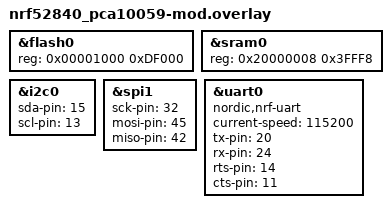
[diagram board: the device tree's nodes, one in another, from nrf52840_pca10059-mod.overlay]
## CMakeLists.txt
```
cmake_minimum_required(VERSION 3.8.2)
set(QEMU_EXTRA_FLAGS -s)

#######################################################
### OPTIONS ###    REMEMBER TO RUN cmake.sh WHEN    ###
#                   YOU MAKE CHANGES IN OPTIONS!    ###
#######################################################

# typical options for USB dongle pca10059 (comment next 3 lines if NOT USB dongle)
OPTION(DEBUG "Set this ON for debug mode (on SDK shows dbg_log messages)" OFF)
OPTION(USB_DONGLE "Set this ON for USB dongle version" ON)
OPTION(BT_MAC "Set this to force hardcoded BT MAC address" OFF)

# typical options for SDK board pca10056 (comment next 3 lines if NOT USDK board)
#OPTION(DEBUG "Set this ON for debug mode (on SDK shows dbg_log messages)" ON)
#OPTION(USB_DONGLE "Set this ON for USB dongle version" OFF)
#OPTION(BT_MAC "Set this to force hardcoded BT MAC address" ON)

IF(USB_DONGLE)
  SET(BOARD nrf52840_pca10059)
  ADD_DEFINITIONS(-DUSB_DONGLE)
ELSE()
  SET(BOARD nrf52840_pca10056)
  IF(DEBUG)
    ADD_DEFINITIONS(-DDEBUG)
    SET(CMAKE_BUILD_TYPE Debug)
  ENDIF()
ENDIF()

IF(BT_MAC)
  ADD_DEFINITIONS(-DBT_MAC)
ENDIF()

ADD_DEFINITIONS(-DIN3_MATH_LITE)

#######################################################

include($ENV{ZEPHYR_BASE}/cmake/app/boilerplate.cmake NO_POLICY_SCOPE)
project(NONE)

target_sources(app PRIVATE
	src/main.c
	src/fsm.c
	src/rent.c
)

# include core in the headers
include_directories ("${PROJECT_SOURCE_DIR}/../core")
#include_directories ("${PROJECT_SOURCE_DIR}/../eth_full")
include_directories ("${PROJECT_SOURCE_DIR}/../eth_nano")
#include_directories ("${PROJECT_SOURCE_DIR}/../eth_basic")
include(../core/include.cmake)

# choose which module to include
#include(../eth_basic/include.cmake)
include(../eth_nano/include.cmake)
include(../core/compiler.cmake)
set_property(GLOBAL PROPERTY C_STANDARD 99)

# add dependency
# add_subdirectory( ../core "${PROJECT_BINARY_DIR}/core")
#target_link_libraries(app core)
```

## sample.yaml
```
sample:
  description: in3 receiver
  name: in3-receiver
  platforms: all
common:
    tags: samples
    harness: console
    harness_config:
      type: one_line
      regex:
        - "Hello World! (.*)"
tests:
  sample.helloworld.singlethread:
    extra_args: CONF_FILE=prj_single.conf
    filter: not CONFIG_BT and not CONFIG_GPIO_SCH and ASSERT == 0
  sample.helloworld.multithread:
    tags: samples
```

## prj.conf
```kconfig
CONFIG_PRINTK=y
#CONFIG_HEAP_MEM_POOL_SIZE=131072
CONFIG_HEAP_MEM_POOL_SIZE=98304
#CONFIG_MAIN_STACK_SIZE=8192
CONFIG_MAIN_STACK_SIZE=12288
CONFIG_SYSTEM_WORKQUEUE_STACK_SIZE=4096

CONFIG_RTT_CONSOLE=n

CONFIG_GPIO=y
CONFIG_BT=y
CONFIG_BT_DEBUG_LOG=n
CONFIG_BT_PERIPHERAL=y
CONFIG_BT_PRIVACY=n
CONFIG_BT_ATT_PREPARE_COUNT=2
CONFIG_BT_GATT_CLIENT=y
CONFIG_BT_L2CAP_DYNAMIC_CHANNEL=n
CONFIG_BT_TINYCRYPT_ECC=n
CONFIG_BT_DEVICE_NAME="in3-peripheral"
CONFIG_BT_DEVICE_NAME_DYNAMIC=y
CONFIG_BT_DEVICE_NAME_MAX=20
CONFIG_BT_ID_MAX=4
CONFIG_BT_RX_BUF_COUNT=10
CONFIG_BT_RX_BUF_LEN=258
CONFIG_BT_L2CAP_TX_MTU=247
CONFIG_BT_L2CAP_TX_FRAG_COUNT=6
CONFIG_BT_L2CAP_TX_BUF_COUNT=10
CONFIG_BT_CONN_TX_MAX=10
CONFIG_BT_ATT_PREPARE_COUNT=10
CONFIG_BT_ID_MAX=4
CONFIG_BT_CTLR_RX_BUFFERS=10
CONFIG_BT_CTLR_TX_BUFFERS=10
CONFIG_BT_CTLR_TX_BUFFER_SIZE=251
CONFIG_BT_CTLR_DATA_LENGTH_MAX=251

CONFIG_BT_SETTINGS=y
CONFIG_FLASH=y
CONFIG_FLASH_PAGE_LAYOUT=y
CONFIG_FLASH_MAP=y
CONFIG_FCB=y
CONFIG_SETTINGS=y
CONFIG_SETTINGS_FCB=y

# config PWM
#-----------
CONFIG_PWM=y
CONFIG_PWM_NRF5_SW=y
CONFIG_PWM_NRF5_SW_0_CLOCK_PRESCALER=4
```

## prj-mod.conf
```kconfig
# config console and stdout
#--------------------------
CONFIG_CONSOLE_SUBSYS=y
CONFIG_CONSOLE_GETCHAR=y
CONFIG_STDOUT_CONSOLE=y
CONFIG_UART_CONSOLE=y
CONFIG_RTT_CONSOLE=n
CONFIG_PRINTK=y

# config UART
#------------
CONFIG_UART_NRFX=y
CONFIG_UART_0_NRF_UART=y
CONFIG_UART_0_NRF_FLOW_CONTROL=n

# config I/O
#-----------
CONFIG_GPIO=y
# NOTE: P0.09 and P0.10 usually set for NFC; to free them use next line
CONFIG_NFCT_PINS_AS_GPIOS=y

# config SPI
#-----------
CONFIG_SPI=y
CONFIG_SPI_NRFX=y
CONFIG_SPI_1=y
CONFIG_SPI_1_NRF_SPI=y

# config I2C
#-----------
CONFIG_I2C=y
CONFIG_I2C_NRFX=y
CONFIG_I2C_0=y
CONFIG_I2C_0_NRF_TWI=y

# config PWM
#-----------
CONFIG_PWM=y
CONFIG_PWM_NRF5_SW=y
CONFIG_PWM_NRF5_SW_0_CLOCK_PRESCALER=4

# config RTOS
#------------
#CONFIG_HEAP_MEM_POOL_SIZE=131072
CONFIG_HEAP_MEM_POOL_SIZE=98304
#CONFIG_MAIN_STACK_SIZE=8192
CONFIG_MAIN_STACK_SIZE=12288
CONFIG_SYSTEM_WORKQUEUE_STACK_SIZE=4096

# config flash
#-------------
#CONFIG_FLASH=y
#CONFIG_FLASH_PAGE_LAYOUT=y
#CONFIG_FLASH_MAP=y
#CONFIG_FCB=y
#CONFIG_SETTINGS=y
#CONFIG_SETTINGS_FCB=y

# config Bluetooth
#-----------------
CONFIG_BT_SETTINGS=n
# n means that state and configuration are NOT stored permanently
CONFIG_BT_DEBUG_LOG=n
# we don't need debug info for bluetooth (at least, I hope so)
CONFIG_BT_PRIVACY=n
# local privacy not enabled
CONFIG_BT_PERIPHERAL=y
# set LE Peripheral role support
CONFIG_BT_DEVICE_APPEARANCE=384
# 384 = BLE_APPEARANCE_GENERIC_REMOTE_CONTROL 
CONFIG_BT_DEVICE_NAME_DYNAMIC=y
# can change the BLE name dinamically (see bluetooth init in main.c)
CONFIG_BT_DEVICE_NAME_MAX=24
# max length allowed for the name 

#CONFIG_BT_L2CAP_TX_MTU=247
# change max allowable MTU
# note: in this case MTU is not changed from the default (23)
#       for compatibility with Android 5; any request will return 23

CONFIG_BT=y
#CONFIG_BT_SETTINGS=y
CONFIG_BT_PERIPHERAL=y
CONFIG_BT_ATT_PREPARE_COUNT=2
CONFIG_BT_GATT_CLIENT=y
CONFIG_BT_L2CAP_DYNAMIC_CHANNEL=n
CONFIG_BT_TINYCRYPT_ECC=n
CONFIG_BT_DEVICE_NAME="in3-peripheral"
CONFIG_BT_ID_MAX=4
CONFIG_BT_RX_BUF_COUNT=10
CONFIG_BT_RX_BUF_LEN=258
CONFIG_BT_L2CAP_TX_MTU=247
CONFIG_BT_L2CAP_TX_FRAG_COUNT=6
CONFIG_BT_L2CAP_TX_BUF_COUNT=10
CONFIG_BT_CONN_TX_MAX=10
CONFIG_BT_ATT_PREPARE_COUNT=10
CONFIG_BT_ID_MAX=4
CONFIG_BT_CTLR_RX_BUFFERS=10
CONFIG_BT_CTLR_TX_BUFFERS=10
CONFIG_BT_CTLR_TX_BUFFER_SIZE=251
CONFIG_BT_CTLR_DATA_LENGTH_MAX=251
```

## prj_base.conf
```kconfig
# nothing here
CONFIG_SCHED_MULTIQ=y
CONFIG_PRINTK=y
CONFIG_HEAP_MEM_POOL_SIZE=65536
#CONFIG_MPU_ALLOW_FLASH_WRITE=y

CONFIG_MAIN_STACK_SIZE=512
CONFIG_SYSTEM_WORKQUEUE_STACK_SIZE=2048

CONFIG_BT_SETTINGS=y
CONFIG_FLASH=y
CONFIG_FLASH_PAGE_LAYOUT=y
CONFIG_FLASH_MAP=y
CONFIG_FCB=y
CONFIG_SETTINGS=y
CONFIG_SETTINGS_FCB=y
CONFIG_BT_MESH_RPL_STORE_TIMEOUT=600

CONFIG_BOOT_BANNER=y
CONFIG_BUILD_TIMESTAMP=y

CONFIG_BT_OBSERVER=y
CONFIG_BT_BROADCASTER=y
CONFIG_BT_CTLR_DUP_FILTER_LEN=0
CONFIG_BT_CTLR_LE_ENC=n
CONFIG_BT_CTLR_LE_PING=n
CONFIG_BT_CTLR_DATA_LENGTH=n
CONFIG_BT_CTLR_PHY=n
CONFIG_BT_CTLR_CHAN_SEL_2=n
CONFIG_BT_CTLR_MIN_USED_CHAN=n
CONFIG_BT_CTLR_ADV_EXT=n
CONFIG_BT_CTLR_PRIVACY=n

CONFIG_BT_PERIPHERAL=y

CONFIG_BT=y
CONFIG_BT_TINYCRYPT_ECC=y
CONFIG_BT_RX_BUF_COUNT=30
CONFIG_BT_L2CAP_RX_MTU=69
CONFIG_BT_L2CAP_TX_MTU=69
CONFIG_BT_L2CAP_TX_BUF_COUNT=8

CONFIG_BT_MESH=y
CONFIG_BT_MESH_RELAY=y
CONFIG_BT_MESH_LOW_POWER=n
CONFIG_BT_MESH_FRIEND=n
CONFIG_BT_MESH_FRIEND_QUEUE_SIZE=16
CONFIG_BT_MESH_ADV_BUF_COUNT=20
#CONFIG_BT_MESH_TX_SEG_MAX=6

CONFIG_BT_MESH_PB_GATT=y
CONFIG_BT_MESH_PB_ADV=y
CONFIG_BT_MESH_GATT_PROXY=y
CONFIG_BT_MESH_CFG_CLI=y

#CONFIG_BT_MESH_LPN_SCAN_LATENCY=30
#CONFIG_BT_MESH_LPN_RECV_DELAY=40
#CONFIG_BT_MESH_LPN_POLL_TIMEOUT=300

CONFIG_BT_MESH_SUBNET_COUNT=2
CONFIG_BT_MESH_APP_KEY_COUNT=2
CONFIG_BT_MESH_MODEL_KEY_COUNT=2
CONFIG_BT_MESH_MODEL_GROUP_COUNT=2
CONFIG_BT_MESH_LABEL_COUNT=3

#CONFIG_BT_MESH_IV_UPDATE_TEST=y

CONFIG_UART_CONSOLE=y

# this outputs btmon formatted data to the serial port
#CONFIG_BT_DEBUG_MONITOR=y

#CONFIG_SYS_LOG=y
CONFIG_SYS_LOG_DEFAULT_LEVEL=4
CONFIG_SYS_LOG_EXT_HOOK=y
CONFIG_BT_DEBUG_LOG=y

CONFIG_BT_MESH_DEBUG=y
#CONFIG_BT_MESH_DEBUG_PROV=y
#CONFIG_BT_MESH_DEBUG_PROXY=y
#CONFIG_BT_MESH_DEBUG_BEACON=y
#CONFIG_BT_MESH_DEBUG_NET=y
#CONFIG_BT_MESH_DEBUG_TRANS=y
#CONFIG_BT_MESH_DEBUG_LOW_POWER=y
#CONFIG_BT_MESH_DEBUG_FRIEND=y
#CONFIG_BT_MESH_DEBUG_MODEL=y
#CONFIG_BT_MESH_DEBUG_ACCESS=y
#CONFIG_BT_MESH_DEBUG_CRYPTO=y
#CONFIG_BT_MESH_DEBUG_ADV=y
#CONFIG_BT_MESH_SELF_TEST=y

#CONFIG_BT_HCI_VS_EXT=n

#CONFIG_STACK_USAGE=y

CONFIG_BT_RX_STACK_SIZE=4096

#CONFIG_BT_DEBUG_HCI_DRIVER=y
#CONFIG_BT_DEBUG_HCI_CORE=y
#CONFIG_BT_DEBUG_GATT=y
#CONFIG_BT_DEBUG_CONN=y

CONFIG_BT_MAX_CONN=1
CONFIG_BT_CTLR_RX_BUFFERS=6
CONFIG_BT_CTLR_TX_BUFFERS=4
CONFIG_BT_HCI_CMD_COUNT=4

CONFIG_BT_ATT_PREPARE_COUNT=2

#CONFIG_NET_BUF_SIMPLE_LOG=y
#CONFIG_SYS_LOG_NET_BUF_LEVEL=4
#CONFIG_NET_BUF_LOG=y
#CONFIG_BT_CTLR_DEBUG_PINS=y
```

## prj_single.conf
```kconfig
CONFIG_MULTITHREADING=n
```

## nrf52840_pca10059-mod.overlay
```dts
&flash0 {
	reg = <0x00001000 0xDF000>;
};

&sram0 {
	reg = <0x20000008 0x3FFF8>;
};

&i2c0 {
	status = "ok";
	sda-pin = <15>;
	scl-pin = <13>;
};

&spi1 {
	status = "ok";
	sck-pin = <32>;
	mosi-pin = <45>;
	miso-pin = <42>;
};

&uart0 {
	compatible = "nordic,nrf-uart";
	current-speed = <115200>;
	status = "ok";
	tx-pin = <20>;
	rx-pin = <24>;
	rts-pin = <14>;
	cts-pin = <11>;
};
```

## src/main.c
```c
#include <stdio.h>
#include <string.h>
#include <zephyr.h>
#include <misc/util.h>
#include <kernel.h>
#include <misc/printk.h>
#include <string.h>
#include <gpio.h>
#include <device.h>
#include <pwm.h>

#include <settings/settings.h>

#include <bluetooth/hci.h>
#include <bluetooth/gatt.h>
#include <bluetooth/bluetooth.h>
#include <bluetooth/conn.h>
#include <bluetooth/l2cap.h>
#include <bluetooth/rfcomm.h>
#include <bluetooth/sdp.h>

#include "fsm.h"
#include "util/utils.h"
#include "util/bytes.h"

#include "util/debug.h"

// prototypes:
void bt_dev_show_info(void);
int start_message(int size);
void process_msg(void);

// variables:
static struct bt_conn *default_conn = NULL;
static struct bt_gatt_ccc_cfg req_ccc_cfg[BT_GATT_CCC_MAX] = {};

static u32_t cnt;
struct device *ledpower; // green led (power)
struct device *ledstrip; // led strip (used as lamp)
struct device *lockpin; // lock out
struct device *gpio; // using blue led on usb board for testing
struct device *pwm_dev; // door servo driver
//struct device *demoRled; // USB demo Rled
//struct device *demoGled; // USB demo Gled
//struct device *demoBled; // USB demo Bled
 
/*
static u8_t gbuff1[32768]; // test buffer -DEBUG ONLY-
static u8_t gbuff2[32768]; // test buffer -DEBUG ONLY-
static u8_t gbuff3[32768]; // test buffer -DEBUG ONLY-
static u8_t gbuff4[8192]; // test buffer -DEBUG ONLY-
*/

static u8_t recv_buf_static[512];
static u8_t req_buf[512];

static u8_t *recv_buf;
static u32_t b_off;
static u32_t total_len;

static u32_t start, end;
static struct in3_client *client;

/////////////////////////////
// callbacks for BT services:
//
static ssize_t read_req(struct bt_conn *conn, const struct bt_gatt_attr *attr, // callback from: BT_GATT_CHARACTERISTIC (req_char_uuid)
			void *buf, u16_t len, u16_t offset)
{
	const char *value = attr->user_data;
	u16_t value_len;

	dbg_log("<--- read req (len=%u ofs=%u)\n", len, offset);

	value_len = min(strlen(value), sizeof(req_buf)); // limit the length to req_buf size

	return bt_gatt_attr_read(conn, attr, buf, len, offset, value, value_len);
}

static ssize_t rx_data(struct bt_conn *conn, const struct bt_gatt_attr *attr,
			 const void *buf, u16_t len, u16_t offset,
			 u8_t flags)
{
	dbg_log("<--- len:%u\n", len);
	// if processing a message don't take new ones
	if (client->msg->ready)
		{
		dbg_log("<--- write req rejected (another message being processed)!!!\n");
		return BT_GATT_ERR(BT_ATT_ERR_WRITE_REQ_REJECTED);
		}
/*
	if (total_len == 0) {
		int mtu = bt_gatt_get_mtu(conn) - 3;
		dbg_log(" GATT MTU: %d, DATA_SIZE: %d len=%d\n", mtu+3, mtu, len);
	}
*/
	if (len == 0x8) {
		char magic[17];
		char *header = (char *) buf;
		if (total_len > 0) {
			dbg_log("<--- Channel already open, dismissing new request\n");
			return BT_GATT_ERR(BT_ATT_ERR_WRITE_REQ_REJECTED);
		}
		sprintf(magic, "%02x%02x%02x%02x%02x%02x%02x%02x", header[0], header[1],
			header[2], header[3], header[4], header[5], header[6], header[7]);
		if (header[0] == 0x69 &&
		    header[1] == 0x6e &&
		    header[2] == 0x33 &&
		    header[3] == 0x63) {
			dbg_log("<--- Magic: 0x%s\n", magic);
			if (start_message(*((int *) buf+1)))
				{
				dbg_log("<--- offset error\n");
				return BT_GATT_ERR(BT_ATT_ERR_INVALID_OFFSET);
				}
			bluetooth_clear_req();
			return len;
		}
	}

	if(recv_buf == 0) // if no space allocated
		recv_buf = k_calloc(1, total_len);
	////////////////////////////////////////////////////

	memcpy(recv_buf + b_off, buf, len);
	b_off += len;

	if (b_off >= total_len) {
		end = k_uptime_get_32();
		process_msg();
	}

	return len;
}

static void req_ccc_cfg_changed(const struct bt_gatt_attr *attr, u16_t value) // Callback from: BT_GATT_CCC (req_ccc_cfg, req_ccc_cfg_changed)
{
	dbg_log("<--- value = %u\n", value);
}

// define an UUID for msg_svc (BT_GATT_PRIMARY_SERVICE)
static struct bt_uuid_128 msg_svc_uuid = BT_UUID_INIT_128(
	0x01, 0xde, 0xbc, 0x9a, 0x78, 0x56, 0x34, 0x12,
	0x78, 0x56, 0x34, 0x12, 0x78, 0x56, 0x34, 0x12);

// define an UUID for msg_char (BT_GATT_CHARACTERISTIC #1)
static const struct bt_uuid_128 msg_char_uuid = BT_UUID_INIT_128(
	0x02, 0xde, 0xbc, 0x9a, 0x78, 0x56, 0x34, 0x12,
	0x78, 0x56, 0x34, 0x12, 0x78, 0x56, 0x34, 0x12);

// define an UUID for req_char (BT_GATT_CHARACTERISTIC #2)
static const struct bt_uuid_128 req_char_uuid = BT_UUID_INIT_128(
	0x02, 0xde, 0xbc, 0x9a, 0x78, 0x56, 0x34, 0x12,
	0x78, 0x56, 0x34, 0x12, 0x78, 0x56, 0x34, 0x13);

// define an UUID for notify (BT_GATT_CHARACTERISTIC #3)
static const struct bt_uuid_128 notify_uuid = BT_UUID_INIT_128(
	0x02, 0xde, 0xbc, 0x9a, 0x78, 0x56, 0x34, 0x12,
	0x78, 0x56, 0x34, 0x12, 0x78, 0x56, 0x34, 0x14);

static struct bt_gatt_attr msg_attrs[] = {
		BT_GATT_PRIMARY_SERVICE(&msg_svc_uuid), // [0] primary service

////////////////////////////////////////////////////////////////////////
		BT_GATT_CHARACTERISTIC(&msg_char_uuid.uuid, // [1] characteristic attribute uuid
			BT_GATT_CHRC_WRITE, // char att properties
			BT_GATT_PERM_WRITE | BT_GATT_PERM_PREPARE_WRITE, // char att permissions
			NULL, rx_data, recv_buf_static), // char att read callback, write callback, value

		BT_GATT_CHARACTERISTIC(&req_char_uuid.uuid, // [2] characteristic attribute uuid
			BT_GATT_CHRC_READ, // char att properties
			BT_GATT_PERM_READ, // char att permissions
			read_req, NULL, req_buf), // char att read callback, write callback, value

		BT_GATT_CHARACTERISTIC(&notify_uuid.uuid, // [3] characteristic attribute uuid
			BT_GATT_CHRC_NOTIFY, // char att properties
			BT_GATT_PERM_NONE, // char att permissions
			NULL, NULL, NULL), // char att read callback, write callback, value
////////////////////////////////////////////////////////////////////////

		BT_GATT_CCC(req_ccc_cfg, req_ccc_cfg_changed), // [4] initial config, callback to configuration change
};

////////
// Code:
//
int start_message(int size)
{
	int old_len = total_len;
	total_len = size;
	dbg_log("RX Message (length: %lu bytes)\n", total_len);

	if (recv_buf && (old_len > total_len)) {
		memset(recv_buf, 0, total_len);
		goto out;
	}

	if (recv_buf)
		k_free(recv_buf);

	recv_buf = k_calloc(1, total_len * sizeof(char));

out:
	if (!recv_buf) {
		dbg_log("Error allocating RX buf (size=%lu)\n", total_len);
		return -1;
	}

	start = k_uptime_get_32();

	k_mutex_lock(&client->mutex, 5000);

	return 0;
}

void process_msg(void)
{
	client->msg->data = recv_buf;
	client->msg->size = total_len;

	client->msg->ready = 1;

	b_off = 0;
	total_len = 0;

	k_mutex_unlock(&client->mutex);
	in3_signal_event();
}

void clear_message(struct in3_client *c)
{
	// EFmod: in case of raw message received, msg->ready flag will NOT be reset
	//  and this may hang the program; so, do this anyway:
	c->msg->ready = 0; // EFmod - may be also this is unassigned

	if (!recv_buf)
		return;

	k_free(recv_buf);

	c->msg->size = 0;
	c->msg->ready = 0;

	b_off = 0;
	total_len = 0;

	recv_buf = 0;
	c->msg->data = 0;
}

static struct bt_gatt_service msg_svc = BT_GATT_SERVICE(msg_attrs);

static const struct bt_data ad_discov[] = {
	BT_DATA_BYTES(BT_DATA_FLAGS, (BT_LE_AD_GENERAL | BT_LE_AD_NO_BREDR)),
};

static void connected(struct bt_conn *conn, u8_t err)
{
	dbg_log("<---\n"); // function is shown on the left
	default_conn = conn;
}

static void disconnected(struct bt_conn *conn, u8_t reason)
{
	dbg_log("<---\n"); // function is shown on the left
}

static bool le_param_req(struct bt_conn *conn, struct bt_le_conn_param *param)
{
int mtu = bt_gatt_get_mtu(conn);

	dbg_log("<--- req MTU=%d\n", mtu);
	return true;
}

static void le_param_updated(struct bt_conn *conn, u16_t interval, u16_t latency, u16_t timeout)
{
int mtu = bt_gatt_get_mtu(conn);

	dbg_log("<--- upd MTU=%d\n", mtu);
	return;
}

static struct bt_conn_cb conn_cbs = {
	.connected = connected,
	.disconnected = disconnected,
	.le_param_req = le_param_req,
	.le_param_updated = le_param_updated,
};

static void bt_ready(int err)
{
	default_conn = NULL;
	bt_conn_cb_register(&conn_cbs);
}

void bluetooth_write_req(char *msg)
{
	k_mutex_lock(&client->mutex, 5000);

	if (strlen(msg) > sizeof(recv_buf_static)) // EFmod: may be req_buf ?
		return;

	strcpy(req_buf, msg);
	dbg_log("<--- buffer prepared for req_char:\n%s\n", req_buf);

	k_mutex_unlock(&client->mutex);

	dbg_log("send notification for REQ\n");

	char *send = "REQ_READY";
//  EFmod: the "normal" [3] does not work. Index [5] is out of bounds, but it works...
	bt_gatt_notify(NULL, &msg_attrs[5], send, strlen(send));
}

void bluetooth_clear_req(void)
{
	memset(req_buf, 0, sizeof(recv_buf_static)); // EFmod: may be sizeof(req_buf) ?
}

#ifdef BT_MAC // START block: next 3 functions needed only if hardcoded BT MAC is enabled
///////////////////////////////////////////////////////////////////////////////
static int char2hex(const char *c, u8_t *x)
{
	if (*c >= '0' && *c <= '9') {
		*x = *c - '0';
	} else if (*c >= 'a' && *c <= 'f') {
		*x = *c - 'a' + 10;
	} else if (*c >= 'A' && *c <= 'F') {
		*x = *c - 'A' + 10;
	} else {
		return -EINVAL;
	}

	return 0;
}

static int str2bt_addr(const char *str, bt_addr_t *addr)
{
	int i, j;
	u8_t tmp;

	if (strlen(str) != 17) {
		return -EINVAL;
	}

	for (i = 5, j = 1; *str != '\0'; str++, j++) {
		if (!(j % 3) && (*str != ':')) {
			return -EINVAL;
		} else if (*str == ':') {
			i--;
			continue;
		}

		addr->val[i] = addr->val[i] << 4;

		if (char2hex(str, &tmp) < 0) {
			return -EINVAL;
		}

		addr->val[i] |= tmp;
	}

	return 0;
}

static int str2bt_addr_le(const char *str, const char *type, bt_addr_le_t *addr)
{
	int err;

	err = str2bt_addr(str, &addr->a);
	if (err < 0) {
		return err;
	}

	if (!strcmp(type, "public") || !strcmp(type, "(public)")) {
		addr->type = BT_ADDR_LE_PUBLIC;
	} else if (!strcmp(type, "random") || !strcmp(type, "(random)")) {
		addr->type = BT_ADDR_LE_RANDOM;
	} else {
		return -EINVAL;
	}

	return 0;
}
#endif
///////////////////////////////////////////////////////////////////// END block

static void byte_to_hex(uint8_t b, char *s)
{
	s[0] = (b / 16) + '0'; // get high nibble, add ascii '0'
	if(s[0] > '9') s[0] += 7; // convert 10..15 to 'A'..'F' (+= 39 if 'a'..'f')
	s[1] = (b & 15) + '0'; // get low nibble, add ascii '0'
	if(s[1] > '9') s[1] += 7; // convert 10..15 to 'A'..'F' (+= 39 if 'a'..'f')
	s[2] = '\0'; // null terminate
}

int bluetooth_setup(struct in3_client *c)
{
	int err, lnam, fmac;
	size_t ad_len, scan_rsp_len = 0;
	struct bt_le_adv_param param;
	const struct bt_data *ad = 0, *scan_rsp = 0;
	char deviceName[20] = "in3-"; // look in prj.con (max length fixed to 20 chars)

#ifdef BT_MAC // if enabled, hardcode the BT MAC address
	bt_addr_le_t addr;
//	char *c_addr = "d3:6c:29:4b:6b:45";
	char *c_addr = "c0:00:00:00:00:00"; // EFmod: most significative 2 bits must be 1
	char *c_addr_type = "(random)";
	err = str2bt_addr_le(c_addr, c_addr_type, &addr);
	bt_set_id_addr((const bt_addr_le_t *) &addr);
#endif

	err = bt_enable(bt_ready);
	if (err) {
		dbg_log("Unable to setup bluetooth");
		return -1;
	}

	k_sleep(1000);
	bt_dev_show_info();

	param.id = 0;
	param.interval_min = BT_GAP_ADV_FAST_INT_MIN_2;
	param.interval_max = BT_GAP_ADV_FAST_INT_MAX_2;
	param.options = (BT_LE_ADV_OPT_CONNECTABLE |
				 BT_LE_ADV_OPT_USE_NAME);
	ad = ad_discov;
	ad_len = ARRAY_SIZE(ad_discov);

	if (IS_ENABLED(CONFIG_SETTINGS)) {
		settings_load();
	}

	fmac = NRF_FICR->DEVICEADDR[0]; // get low 4 octets of BT MAC
	lnam = strlen(deviceName); // original name length (before adding the MAC)
    byte_to_hex((fmac & 0xFF000000) >> 24, deviceName +lnam); // add MAC[3]
    byte_to_hex((fmac & 0xFF0000) >> 16, deviceName +lnam +2); // add MAC[2]
    byte_to_hex((fmac & 0xFF00) >> 8, deviceName +lnam +4); // add MAC[1]
    byte_to_hex(fmac & 0xFF, deviceName +lnam +6); // add MAC[0] (byte_to_hex adds \0)
//	bt_set_name(deviceName); // BT name built with "in3-" and NORDIC (almost) unique BT MAC (es: in3-84C8C54B)
	bt_set_name("in3-emiliotest"); // EFmod: use ONLY this for testing with Arda's App

	err = bt_le_adv_start(&param, ad, ad_len, scan_rsp, scan_rsp_len);
	if (err < 0) {
		dbg_log("Failed to start advertising (err %d)\n", err);
		return -1;
	} else {
		dbg_log("Advertising started\n");
	}

	// set client data
	client = c;
	client->msg->data = recv_buf;

	recv_buf = 0;
	b_off = 0;
	total_len = 0;

	dbg_log("Registering GATT service\n");
	err = bt_gatt_service_register(&msg_svc);

	if (err < 0) {
		dbg_log("Failed to register servic\n");
		return -1;
	} else {
		dbg_log("Service registered\n");
	}

	return 0;
}

///////// new GPIO functions
void ledpower_set(int state)
{
	if(state) // if ON
		gpio_pin_write(ledpower, LEDPOWER, 0); // led with negative logic
	else // if OFF
		gpio_pin_write(ledpower, LEDPOWER, 1); // led with negative logic
}

void ledstrip_set(int state)
{
	if(state) // if ON
		gpio_pin_write(ledstrip, LEDSTRIP, 1); // led with positive logic
	else { // if OFF
		gpio_pin_write(ledstrip, LEDSTRIP, 0); // led with positive logic
//		gpio_pin_write(demoGled, LEDG, 1); // negative logic, green led OFF
//		gpio_pin_write(demoRled, LEDR, 1); // negative logic, red led OFF
	}
}

void lock_set(int state)
{
	if(state) // if ON
		gpio_pin_write(lockpin, LOCKPIN, 1); // coil with positive logic
	else // if OFF
		gpio_pin_write(lockpin, LOCKPIN, 0); // coil with positive logic
}

void door_control(int state) // control the motorized door 
{
	if(state == 'o') { // open door
		pwm_pin_set_usec(pwm_dev, 2, 40000, 2000); // P0.2 - 40ms period - 2 mS pulse; piston All-out
//		gpio_pin_write(demoGled, LEDG, 0); // negative logic, green led ON
		return;
	}
	if(state == 'c') { // close door
//		gpio_pin_write(demoRled, LEDR, 0); // negative logic, red led ON
		pwm_pin_set_usec(pwm_dev, 2, 40000, 1000); // P0.2 - 40mS period - 1mS pulse; piston All-in
		return;
	}
}

int gpio_setup(void)
{
	// PWM init ////////////////////////////////////////////////////////
	pwm_dev = device_get_binding("PWM_0");
	if (!pwm_dev) {
		printk("Cannot find PWM device!\n");
	}
	pwm_pin_set_usec(pwm_dev, 2, 40000, 1000); // P0.2 - 40mS period - 1mS pulse; piston All-in (door closed)

	ledpower = device_get_binding(LEDPOWER_PORT); // CONFIG_GPIO_P0_DEV_NAME
	gpio_pin_configure(ledpower, LEDPOWER, GPIO_DIR_OUT); // set as output (see fsm.h)
	ledpower_set(IO_ON);

	ledstrip = device_get_binding(LEDSTRIP_PORT);
	gpio_pin_configure(ledstrip, LEDSTRIP, GPIO_DIR_OUT); // set as output (see fsm.h)
	ledstrip_set(IO_OFF);

	lockpin = device_get_binding(LOCKPIN_PORT);
	gpio_pin_configure(lockpin, LOCKPIN, GPIO_DIR_OUT); // set as output (see fsm.h)
	lock_set(IO_OFF);
/*
	demoRled = device_get_binding(CONFIG_GPIO_P0_DEV_NAME); // Rled is P0.08
	gpio_pin_configure(demoRled, LEDR, GPIO_DIR_OUT); // set as output (see fsm.h)
	gpio_pin_write(demoRled, LEDR, 1); // negative logic, led OFF

	demoGled = device_get_binding(CONFIG_GPIO_P1_DEV_NAME); // Gled is P1.09
	gpio_pin_configure(demoGled, LEDG, GPIO_DIR_OUT); // set as output (see fsm.h)
	gpio_pin_write(demoGled, LEDG, 1); // negative logic, led OFF

	demoBled = device_get_binding(CONFIG_GPIO_P0_DEV_NAME); // Gled is P0.12
	gpio_pin_configure(demoBled, LEDB, GPIO_DIR_OUT); // set as output (see fsm.h)
	gpio_pin_write(demoBled, LEDB, 1); // negative logic, led OFF
*/
	for(int i = 0, cnt = 0; i < 5; i++, cnt++) // blink led and terminate ON
		{
		ledpower_set(cnt % 2);
		k_sleep(200);
		}
	ledpower_set(IO_ON);
	return 0;
}
/////////////////////// end of new GPIO functions

void main(void)
{
	dbg_log("\n\n\n\n\n***\n*** Starting in3_client...\n");
/*
	memset(gbuff1, 0x55, 32768); // fill buffer with 0x55
	dbg_log("Buff1 set...\n");
	memset(gbuff2, 0x55, 32768); // fill buffer with 0x55
	dbg_log("Buff2 set...\n");
	memset(gbuff3, 0x55, 32768); // fill buffer with 0x55
	dbg_log("Buff3 set...\n");
	memset(gbuff4, 0x55, 8192); // fill buffer with 0x55
	dbg_log("Buff4 set...\n");
*/
	in3_client_start();

	return;
}
```

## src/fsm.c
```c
#include <kernel.h>
#include <misc/printk.h>
#include <stdio.h>
#include <string.h>

#include "fsm.h"
#include "rent.h"
#include "util/utils.h"
#include <eth_nano.h>

#include "util/debug.h"

// Global Client
struct in3_client*  client;
struct k_timer *timer, *timer1, *timer2, *timer3; // timer structures
int                 undo;

// private
static void timer_expired(struct k_timer* work) {
  undo = 1;
  dbg_log("<--- timer expired\n");
  k_sem_give(&client->sem);
}

static void timer1_expired(struct k_timer *work) // one shot timer (monitor led)
{
	ledpower_set(IO_ON); // power led on
}

static void timer2_expired(struct k_timer *work) // one shot timer (led stripe)
{
	ledstrip_set(IO_OFF); // ledstrip off
}

static void timer3_expired(struct k_timer *work) // one shot timer (lock-coil)
{
	lock_set(IO_OFF); // lock off
}

static void wait_for_event(void) {
  if (!client)
    return;

//  k_sem_take(&client->sem, 600000); // EFnote: 600000 mS = 600 sec = 10 min
  k_sem_take(&client->sem, K_SECONDS(60)); // 60 sec = 1 min
}

void do_action(action_type_t action)
{
	ledpower_set(IO_OFF); // power led off
	k_timer_start(timer1, 250, 0); // start timer 1 initial duration 250mS, period = 0
	if (action == LOCK)
		{
		dbg_log("<--- action: LOCK\n");
		ledstrip_set(IO_ON); // led on
		k_timer_start(timer2, 2000, 0); // start timer 2 initial duration 2*1000mS, period = 0
		door_control('c'); // close the door
		}
	else
		{
		dbg_log("<--- action: UNLOCK\n");
		ledstrip_set(IO_ON); // led on
		k_timer_start(timer2, 10000, 0); // start timer 2 initial duration 10*1000mS, period = 0
		lock_set(IO_ON); // lock on
		k_timer_start(timer3, 1500, 0); // start timer 3 initial duration 1500mS, period = 0
		door_control('o'); // open the door
		}
}

// PUBLIC API
void in3_signal_event(void) {
  if (!client)
    return;

  dbg_log("<--- signalling event\n");
  k_sem_give(&client->sem);
}

/////////////////////////////////////

/*******************/
/*  state machine  */
/*******************/

typedef enum {
  STATE_INIT,
  STATE_WAITING,
  STATE_ACTION,
  STATE_RESET,
  STATE_MAX
} in3_state_t;

typedef in3_state_t in3_state_func_t(void);

static in3_state_t in3_init(void) {
	client = k_calloc(1, sizeof(struct in3_client));
	timer = k_calloc(1, sizeof(struct k_timer));
	timer1 = k_calloc(1, sizeof(struct k_timer)); // allocate 1 array element of K_timer size
	timer2 = k_calloc(1, sizeof(struct k_timer)); // allocate 1 array element of K_timer size
	timer3 = k_calloc(1, sizeof(struct k_timer)); // allocate 1 array element of K_timer size

	client->in3               = in3_new();
	client->in3->chainId      = 0x044d;
	client->in3->requestCount = 1;
	client->in3->max_attempts=1;

	client->txr = k_calloc(1, sizeof(in3_tx_receipt_t));
	client->msg = k_calloc(1, sizeof(in3_msg_t));

	in3_register_eth_nano();
	bluetooth_setup(client);
 	gpio_setup();

	k_sem_init(&client->sem, 0, 1);
	k_mutex_init(&client->mutex);
	k_timer_init(timer, timer_expired, NULL);
	k_timer_init(timer1, timer1_expired, NULL); // init timer, callback for expired, callback for stopped
	k_timer_init(timer2, timer2_expired, NULL); // init timer, callback for expired, callback for stopped
	k_timer_init(timer3, timer3_expired, NULL); // init timer, callback for expired, callback for stopped

	return STATE_WAITING;
}

static in3_state_t in3_waiting(void) {
  k_mutex_lock(&client->mutex, 10000);
  if (client->msg->ready) {
  	dbg_log("<--- data received (len=%i):\n\n%s\n\n", strlen(client->msg->data), client->msg->data);
    client->msg->start = k_uptime_get_32();
    if (msg_get_type(client->msg->data) == T_ACTION) {
      k_mutex_unlock(&client->mutex);
      return STATE_ACTION;
    }
    client->msg->end = k_uptime_get_32();
    dbg_log("<--- total time: %lums\n", (unsigned long) client->msg->end - client->msg->start);
    clear_message(client);
  }

  k_mutex_unlock(&client->mutex);
  wait_for_event();

  if (undo) {
    do_action(LOCK);
    undo = 0;
  }

  return STATE_WAITING;
}

static in3_state_t in3_action(void) {
  int           err;
  action_type_t action = msg_get_action(client->msg->data);

  if (action != LOCK && action != UNLOCK)
    return STATE_RESET;

  // reset rental
  if (client->rent) {
    k_free(client->rent->controller);
    k_free(client->rent);
  }

	client->rent = k_calloc(1, sizeof(in3_rental_t));
	client->rent->when = json_get_int_value(client->msg->data, "timestamp");

  err = verify_rent(client);
  if (err) {
    dbg_log("<--- Invalid rental\n");
    return STATE_RESET;
  }

  do_action(action);

//  if (action == UNLOCK)
//    k_timer_start(timer, K_SECONDS(5), 0);

  return STATE_RESET;
}

static in3_state_t in3_reset(void) {
  client->msg->end = k_uptime_get_32();

  dbg_log("<--- Total time: %lums\n", (unsigned long) client->msg->end - client->msg->start);
  clear_message(client);

  return STATE_WAITING;
}

in3_state_func_t* const state_table[STATE_MAX] = {
    in3_init,
    in3_waiting,
    in3_action,
    in3_reset,
    NULL
  };

static in3_state_t run_state(in3_state_t state) {
  return state_table[state]();
}

int in3_client_start(void) {
  in3_state_t state = STATE_INIT;

  while (1) {
    switch(state)
      {
      case STATE_INIT:
        dbg_log("<--- INIT\n");
        break;
      case STATE_WAITING:
        dbg_log("<--- WAITING\n");
        break;
      case STATE_ACTION:
        dbg_log("<--- ACTION\n");
        break;
      case STATE_RESET:
        dbg_log("<--- RESET\n");
        break;
      default:
        dbg_log("<--- STATE MACHINE ERROR!\n");
        state = STATE_RESET; // force state to reset
        break;
      }
    state = run_state(state);
  }
}
```

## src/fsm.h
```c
#include <zephyr.h>
#include "client/client.h"

#include "util/bytes.h"

// USB & SDK I/O defines
// defines:
#define CONFIG_GPIO_P0_DEV_NAME	"GPIO_0"
#define CONFIG_GPIO_P1_DEV_NAME	"GPIO_1"

#define IO_ON	1	// IO line ON (high level)
#define IO_OFF	0	// IO line OFF (low level)

#ifndef USB_DONGLE // if USB dongle is NOT enabled

 // SDK board I/O defines
 #define LEDPOWER_PORT	CONFIG_GPIO_P0_DEV_NAME
 #define LEDPOWER		13 // LED1 on PCA10056 (SDK)

 #define LEDSTRIP_PORT	CONFIG_GPIO_P0_DEV_NAME
 #define LEDSTRIP		14 // LED2 on PCA10056 (SDK)

 #define LOCKPIN_PORT	CONFIG_GPIO_P0_DEV_NAME
 #define LOCKPIN			15 // LED3 on PCA10056 (SDK)

#else // if USB dongle is used

 // USB board I/O defines
 #define LEDPOWER_PORT	CONFIG_GPIO_P0_DEV_NAME
 #define LEDPOWER		6 // LED1 on PCA10059 (USB)

 #define LEDSTRIP_PORT	CONFIG_GPIO_P1_DEV_NAME
 #define LEDSTRIP		15 // P1.15 on PCA10059 (USB)

 #define LOCKPIN_PORT	CONFIG_GPIO_P0_DEV_NAME
 #define LOCKPIN			31 // P0.31 on PCA10059 (USB)

 // -> some others USB board useful I/Os
 #define LEDR_PORT	CONFIG_GPIO_P0_DEV_NAME
 #define LEDR		8 // LED2 Red on PCA10059 (USB)
 #define LEDG_PORT	CONFIG_GPIO_P1_DEV_NAME
 #define LEDG		9 // LED2 Green on PCA10059 (USB)
 #define LEDB_PORT	CONFIG_GPIO_P0_DEV_NAME
 #define LEDB		12 // LED2 Blue on PCA10059 (USB)

#endif

// Messaging

typedef enum {
	T_ERROR = 0,
	T_ACTION,
	T_REQUEST,
	T_RESPONSE
} msg_type_t;

typedef enum {
	NONE,
	UNLOCK,
	LOCK
} action_type_t;

typedef struct {
	int from;
	int until;
	int when;
	char *devid;
	char *controller;
} in3_rental_t;

typedef struct {
	char *hash;
	char *data;
} in3_tx_receipt_t;

// Client State Machine

typedef struct {
	int ready;
	int type;
	int size;
	char *data;
	u32_t start;
	u32_t end;
} in3_msg_t;

struct in3_client {
	in3_t* in3;
	struct k_sem sem;
	struct k_mutex mutex;
	in3_msg_t *msg;
	in3_rental_t *rent;
	in3_tx_receipt_t *txr;
};

void in3_signal_event(void);
int in3_client_start(void);

// Bluetooth and Board functions

int bluetooth_setup(struct in3_client *c);
void bluetooth_write_req(char *msg);
void bluetooth_clear_req(void);
int led_setup(void);
void led_set(int);
void gpio_set(action_type_t);
void clear_message(struct in3_client *c);

int in3_can_rent(struct in3_client *c, char *r, char *amsg);

int gpio_setup(void);
void door_control(int);
void ledpower_set(int);
void ledstrip_set(int);
void lock_set(int);
void do_action(action_type_t action);
```

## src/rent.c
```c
#include "fsm.h"
#include "util/debug.h"
#include "util/stringbuilder.h"
#include <client/client.h>
#include <crypto/ecdsa.h>
#include <crypto/secp256k1.h>
#include <eth_nano.h>
#include <rtc.h>
#include <stdio.h>
#include <string.h>
#include <util/data.h>

msg_type_t msg_get_type(char* c) {
  char buf[20]; // allocate tmp space for string compare

  msg_type_t type = T_ERROR;
  if (strstr(c, "msgType") == 0) // if received string does not contain msgType
    return type;

  // NOTE: check buf size (will need an additional function like json_get_str_length
  //       or to modify json_get_str_value with additional parameter maxlen)

  json_get_str_value(c, "msgType", buf);
  if (strcmp(buf, "action") == 0) // if string match
    type = T_ACTION;
  else if (strcmp(buf, "in3Response") == 0) // if string match
    type = T_RESPONSE;

  return type;
}

action_type_t msg_get_action(char* c) {
  char buf[20]; // allocate tmp space for string compare

  action_type_t type = NONE;
  if (strstr(c, "action") == 0) // if received string does not contain action
    return type;

  // NOTE: check buf size (will need an additional function like json_get_str_length
  //       or to modify json_get_str_value with additional parameter maxlen)

  json_get_str_value(c, "action", buf); // note: check buf size (need some json_get_str_length)
  if (strcmp(buf, "unlock") == 0)       // if string match
    type = UNLOCK;
  else if (strcmp(buf, "lock") == 0) // if string match
    type = LOCK;

  return type;
}

char* msg_get_response(struct in3_client* c) {
  char* val = 0;

  if (!c->msg->ready)
    return T_ERROR;

  val = json_get_json_value(c->msg->data, "responses");
  return val;
}

// get_tx_hash - called by verify_rent (rent.c)
static int get_tx_hash(char* msg, char* dst) {
  *dst = 0;                                        // preset out string as an empty string
  json_get_str_value(msg, "transactionHash", dst); // note: check dst buf len
  if (strncmp(dst, "0x", 2))                       // EFnote: need to check also 0X ???
    return -1;                                     // good
  return 0;                                        // bad
}

// wait_for_message - called by send_ble
int wait_for_message(struct in3_client* c) {
  int i = 100;

  dbg_log("<--- wait_for_message\n");
  while (c->msg->ready == 0 && i--)
    k_sleep(100);

  k_mutex_lock(&c->mutex, 30000);
  k_mutex_unlock(&c->mutex);

  if (c->msg->ready) {
    dbg_log("<--- msg received!\n");
    return 0;
  }
  dbg_log("<--- timeout error!\n");
  return i; // -1 if timeout elapsed
}

static struct in3_client* _client = NULL;

int send_ble(char** urls, int urls_len, char* pl, in3_response_t* result) {
  char payload[5120]; // EFmod -so big ?

  sprintf(payload, "{\"msgType\":\"in3Request\",\"msgId\":1,\"url\":\"%s\",\"method\":\"POST\",\"data\":%s}", *urls, pl);

  clear_message(_client);
  bluetooth_write_req(payload);
  int err = wait_for_message(_client);
  bluetooth_clear_req();

  _client->txr->data = NULL;

  if (err < 0) {
    sb_add_chars(&result->error, "Error receiving this response");
    return err;
  }

  _client->txr->data = msg_get_response(_client);
  sb_add_chars(&result->result, _client->txr->data);
  return 0;
}

// in3_get_tx_receipt - called by verify_rent;
int in3_get_tx_receipt(struct in3_client* c, char* tx_hash, char** response) {
  char  params[512]; // EFmod: (IN3_REQ_FMT string is 240 chars long)
  char* result = NULL;
  char* error  = NULL;

  if (!c || !tx_hash)
    return -1;

  _client           = c;
  c->in3->transport = send_ble;
  // first check if cached receipt matches
  if (c->txr->hash && !strcmp(c->txr->hash, tx_hash)) {
    //clear_message(c);
    *response = c->txr->data;
    return 0;
  }

  k_free(c->txr->data);
  k_free(c->txr->hash);
  memset(c->txr, 0, sizeof(in3_tx_receipt_t));

  sprintf(params, "[\"%s\"]", tx_hash);

  c->in3->transport = send_ble; // Assign the transport function (executed when needed)

  in3_client_rpc(c->in3, "eth_getTransactionReceipt", params, &result, &error);

  if (error) {
    dbg_log("<--- got s error: %s\n", error);
    *response = NULL;
    k_free(error);
  } else {
    c->txr->data = result; // 190131 solves the issue in caching
    *response    = result;
    //TODO don't need it!
    c->txr->hash = k_calloc(1, strlen(tx_hash) + 1);
    c->txr->hash = memcpy(c->txr->hash, tx_hash, strlen(tx_hash));
  }

  return 0;
}

int in3_can_rent(struct in3_client* c, char* resp, char* amsg) {
  int            res = -1, i;
  char           tmp[256], mhash[256];
  json_parsed_t* response = parse_json(resp);
  json_parsed_t* message  = parse_json(amsg);
  d_token_t *    l, *log = NULL;
  bytes_t *      signer = NULL, *hash = NULL;
  bytes_t*       log_rented = hex2byte_new_bytes("9123e6a7c5d144bd06140643c88de8e01adcbb24350190c02218a4435c7041f8", 64);

  if (!response || !message) goto out;

  d_token_t* logs = d_get(response->items, key("logs"));
  if (!logs) goto out;

  for (i = 0, l = logs + 1; i < d_len(logs); i++, l = d_next(l)) {
    if (b_cmp(d_get_bytes_at(d_get(l, key("topics")), 0), log_rented)) {
      log = l;
      break;
    }
  }

  // no event found,
  if (!log) goto out;

  char* url = d_get_string(message->items, "url");
  //bytes_t* deviceId = d_get_bytes_at(d_get(log,key("topics")),1);  // we need to store and compare the deviceId
  bytes_t* data = d_get_bytes(log, "data");

  c->rent->from  = bytes_to_long(data->data + 32, 32);
  c->rent->until = bytes_to_long(data->data + 64, 32);
  //TODO do we need to set it as string?
  c->rent->controller    = _malloc(43);
  c->rent->controller[0] = '0';
  c->rent->controller[1] = 'x';
  bytes_to_hex(data->data + 12, 20, c->rent->controller + 2);

  dbg_log("*** controller: '%s'\n", c->rent->controller);
  dbg_log("*** from: %d, until: %d, when: %d\n", c->rent->from, c->rent->until, c->rent->when);

  // wrong time
  if (c->rent->from >= c->rent->when || c->rent->when >= c->rent->until) goto out;

  // check signature

  // prepare message hash
  sprintf(tmp, "%s%d%s{}", url, c->rent->when, d_get_string(message->items, "action"));
  sprintf(mhash, "\031Ethereum Signed Message:\n%d%s", strlen(tmp), tmp);
  bytes_t msg = {.data = (uint8_t*) &mhash, .len = strlen(mhash)};
  hash        = sha3(&msg);

  // get the signature
  signer = ecrecover_signature(hash, d_get(message->items, key("signature")));
  if (signer == NULL) goto out;

  // check if the signer is the same as the controller in the event.
  // reuse msg to point to the address in the event.
  msg.data = data->data + 12;
  msg.len  = 20;
  if (!b_cmp(signer, &msg)) goto out;

  //TODO check if the url and the deviceid is correct.
  // if (strcmp(url, saved_url)!=0)          goto out;
  // if (!b_comp(device_id, saved_device_id)) goto out;
  // if (!b_comp( d_get_bytes(response,"contractAddress") , saved_contract)) goto out;

  res = 0;

out:
  if (response) _free(response);
  if (message) _free(message);
  if (hash) b_free(hash);
  if (signer) b_free(signer);
  b_free(log_rented);

  return res;
}

// verify_rent - called by in3_action (state machine, fsm.c)
int verify_rent(struct in3_client* c) {
  int   ret = -1, id    = 0;
  char  tx_hash[67], *r = 0;
  char* amsg = 0;
  char  payload[512]; // EFnote: the payload in send_ble is 10 times bigger

  get_tx_hash(c->msg->data, tx_hash); // get tx_hash from msg->data
  if (tx_hash[0] == 0)                // if empty string (errors in get_tx_hash)
    goto out;                         // note: ret = -1

  // keep copy of action message
  amsg = k_calloc(1, sizeof(char) * (c->msg->size + 1));
  amsg = memcpy(amsg, c->msg->data, c->msg->size + 1);
  id   = json_get_int_value(amsg, "msgId");

  in3_get_tx_receipt(c, tx_hash, &r); // try to receive response
  if (r)
    dbg_log("<--- response:\n%s\n", r);

  if (in3_can_rent(c, r, amsg) < 0)
    goto out;

  ret = 0;

out:
  if (ret)
    sprintf(payload, "{\"msgId\":%d,\"msgType\":\"error\",\"error\":\"Invalid rental\"}", id);
  else
    sprintf(payload, "{\"msgId\":%d,\"msgType\":\"action\",\"result\":\"success\"}", id);

  bluetooth_write_req(payload);

  if (amsg)
    k_free(amsg);

  return ret;
}
```
